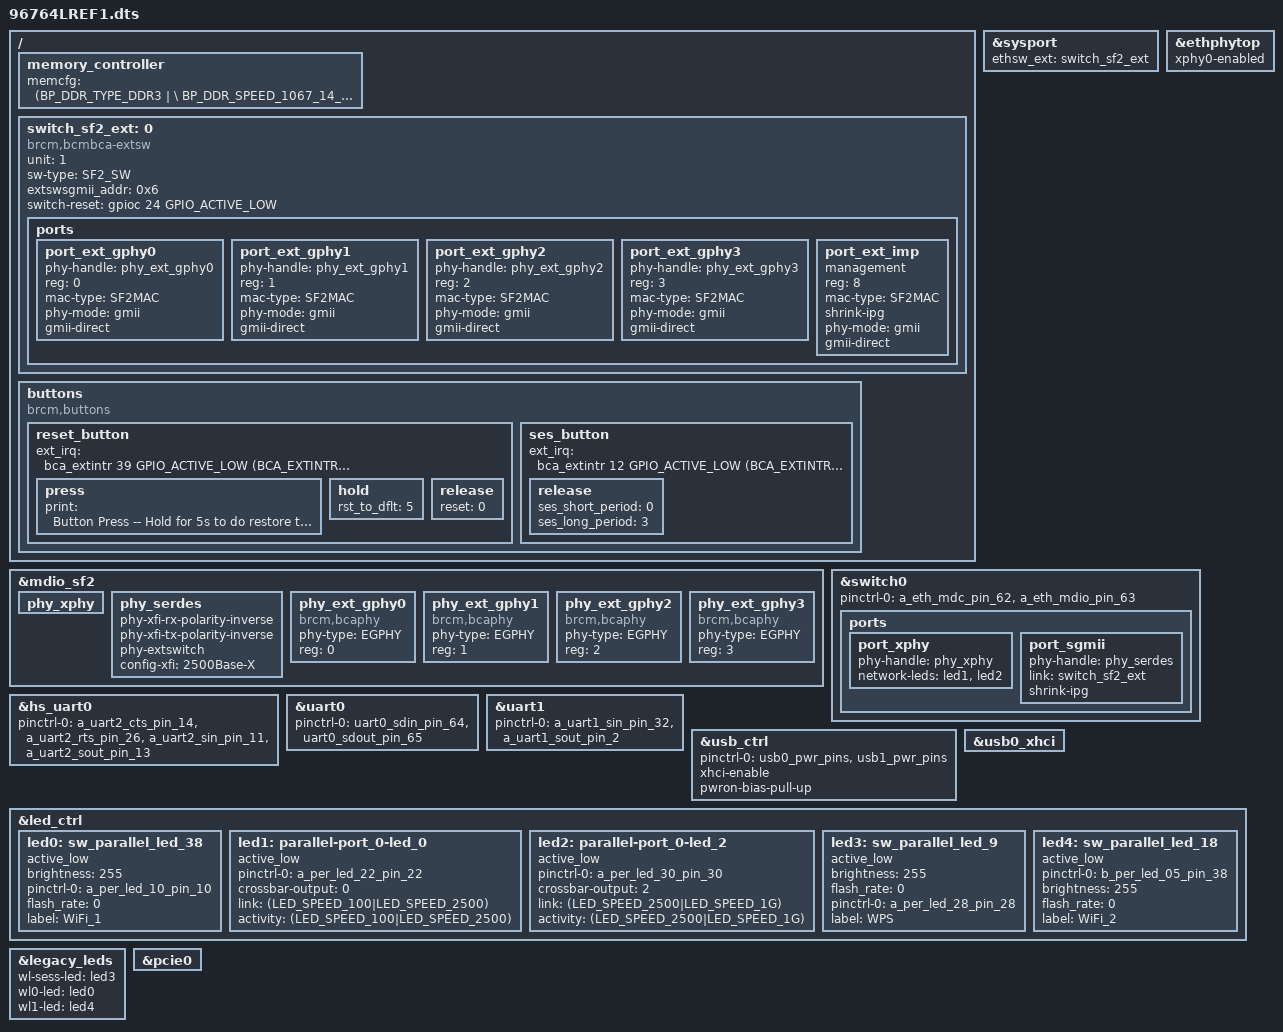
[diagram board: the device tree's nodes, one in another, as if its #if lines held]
#include "6765.dtsi"
#include "../bcm_voice.dtsi"

/ {

	memory_controller {
		memcfg = <(BP_DDR_TYPE_DDR3       | \
			BP_DDR_SPEED_1067_14_14_14    | \
			BP_DDR_TOTAL_SIZE_512MB      | \
			BP_DDR_DEVICE_WIDTH_16        | \
			BP_DDR_TOTAL_WIDTH_16BIT      | \
			BP_DDR_6765_DEFAULT           | \
			BP_DDR_CONFIG_DEBUG)>;
	};
	
	switch_sf2_ext:0 {
	};
};

/ {
	buttons {
		compatible = "brcm,buttons";
		reset_button {
			ext_irq = <&bca_extintr 39 GPIO_ACTIVE_LOW (BCA_EXTINTR_TYPE_LOW_LEVEL | BCA_EXTINTR_TYPE_SENSE_EDGE)>;
			press {
				print = "Button Press -- Hold for 5s to do restore to default";
			};
			hold {
				rst_to_dflt = <5>;
			};
			release {
				reset = <0>;
			};  
		};
		ses_button {
			ext_irq = <&bca_extintr 12 GPIO_ACTIVE_LOW (BCA_EXTINTR_TYPE_LOW_LEVEL | BCA_EXTINTR_TYPE_SENSE_EDGE)>;
			release {
				ses_short_period = <0>;
				ses_long_period = <3>;
			};
		};
	};    
};

&sysport {
    ethsw_ext = <&switch_sf2_ext>;
};

&mdio_sf2 {
       /* Port PHY mapping:
            port_imp -8#0- port_xhy <----> phy_xphy
                      # #
                      ##5- port_sgmii <-> phy_serdes <--> port_ext_imp -8#0- port_ext_gphy0 <--> phy_ext_gphy0
                                                                        # 1- port_ext_gphy1 <--> phy_ext_gphy1
                                                                        # 2- port_ext_gphy2 <--> phy_ext_gphy2
                                                                        ##3- port_ext_gphy3 <--> phy_ext_gphy3
         */
	phy_xphy {
		status = "okay";
		/delete-property/ pinctrl-names;    // handle in switch probing
		/delete-property/ pinctrl-0;
	};
	phy_serdes {
		phy-xfi-rx-polarity-inverse;
		phy-xfi-tx-polarity-inverse;
		phy-extswitch;
		config-xfi="2500Base-X";
		status = "okay";
	};

	/* PHYs on external SF2 switch */
	phy_ext_gphy0:phy_ext_gphy0 {
		compatible = "brcm,bcaphy";
		phy-type = "EGPHY";
		reg = <0>;
		status = "okay";
	};
	phy_ext_gphy1:phy_ext_gphy1 {
		compatible = "brcm,bcaphy";
		phy-type = "EGPHY";
		reg = <1>;
		status = "okay";
	};
	phy_ext_gphy2:phy_ext_gphy2 {
		compatible = "brcm,bcaphy";
		phy-type = "EGPHY";
		reg = <2>;
		status = "okay";
	};
	phy_ext_gphy3:phy_ext_gphy3 {
		compatible = "brcm,bcaphy";
		phy-type = "EGPHY";
		reg = <3>;
		status = "okay";
	};
};

&switch_sf2_ext {                       /* linux/uboot: external sf2 */
	unit = <1>;
	sw-type = "SF2_SW";

	compatible = "brcm,bcmbca-extsw";
	extswsgmii_addr = <0x6>;
	switch-reset = <&gpioc 24 GPIO_ACTIVE_LOW>;

	ports {
		#address-cells = <1>;
		#size-cells = <0>;

		port_ext_gphy0 {
			phy-handle = <&phy_ext_gphy0>;
			reg = <0>;
			mac-type = "SF2MAC";
			phy-mode = "gmii";
			gmii-direct;
			status = "okay";
		};
		port_ext_gphy1 {
			phy-handle = <&phy_ext_gphy1>;
			reg = <1>;
			mac-type = "SF2MAC";
			phy-mode = "gmii";
			gmii-direct;
			status = "okay";
		};
		port_ext_gphy2 {
			phy-handle = <&phy_ext_gphy2>;
			reg = <2>;
			mac-type = "SF2MAC";
			phy-mode = "gmii";
			gmii-direct;
			status = "okay";
		};
		port_ext_gphy3 {
			phy-handle = <&phy_ext_gphy3>;
			reg = <3>;
			mac-type = "SF2MAC";
			phy-mode = "gmii";
			gmii-direct;
			status = "okay";
		};
		port_ext_imp {
			management;                     /* sf2_ext.p8 <--> root.p5  when P8_SGMII_SEL=1 */
			reg = <8>;
			mac-type = "SF2MAC";
			shrink-ipg;
			phy-mode = "gmii";
			gmii-direct;
			status = "okay";
		};
	};
};

&ethphytop {
    xphy0-enabled;
    status = "okay";
};

&switch0 {
	pinctrl-0 = <&a_eth_mdc_pin_62 &a_eth_mdio_pin_63>;
	pinctrl-names = "default";

	ports {
		port_xphy {
			phy-handle = <&phy_xphy>;
			network-leds=<&led1 &led2>;
			status = "okay";
		};
		port_sgmii {
			phy-handle = <&phy_serdes>;
			link = <&switch_sf2_ext>;
			shrink-ipg;
			status = "okay";
		};
	};
};

&hs_uart0 {
	pinctrl-0 = <&a_uart2_cts_pin_14 &a_uart2_rts_pin_26 &a_uart2_sin_pin_11 &a_uart2_sout_pin_13>;
	pinctrl-names = "default";
	status = "okay";
};

&uart0 {
    pinctrl-names = "default";
    pinctrl-0 = <&uart0_sdin_pin_64 &uart0_sdout_pin_65>;
    status = "okay";
};

&uart1 {
    pinctrl-names = "default";
    pinctrl-0 = <&a_uart1_sin_pin_32 &a_uart1_sout_pin_2>;
    status = "okay";
};

&usb_ctrl {
	pinctrl-names="default";
	pinctrl-0 = <&usb0_pwr_pins &usb1_pwr_pins>;
	status = "okay";
	xhci-enable;
	pwron-bias-pull-up;
};

&usb0_xhci {
	status = "okay";
};

&led_ctrl {

	led0: sw_parallel_led_38 {
		active_low; 
		brightness = <255>;
		pinctrl-0 = <&a_per_led_10_pin_10>;
		flash_rate = <0>;
		status = "okay";
		label = "WiFi_1";
	};
	led1: parallel-port_0-led_0 {
		active_low;
		pinctrl-0 = <&a_per_led_22_pin_22>;
		crossbar-output = <0>;
		link = <(LED_SPEED_100|LED_SPEED_2500)>;
		activity = <(LED_SPEED_100|LED_SPEED_2500)>;
		status="okay";
	};
	led2: parallel-port_0-led_2 {
		active_low;
		pinctrl-0 = <&a_per_led_30_pin_30>;
		crossbar-output = <2>;
		link = <(LED_SPEED_2500|LED_SPEED_1G)>;
		activity = <(LED_SPEED_2500|LED_SPEED_1G)>;
		status="okay";
	};
	led3: sw_parallel_led_9 {
		active_low; 
		brightness = <255>;
		flash_rate = <0>;
		pinctrl-0 = <&a_per_led_28_pin_28>;
		status = "okay";
		label = "WPS";
	};

	led4: sw_parallel_led_18 {
		active_low; 
		pinctrl-0 = <&b_per_led_05_pin_38>;
		brightness = <255>;
		flash_rate = <0>;
		status = "okay";
		label = "WiFi_2";
	};

};

&legacy_leds {
	wl-sess-led = <&led3>;
	wl0-led = <&led0>;
	wl1-led = <&led4>;
};

#if defined(CONFIG_BCM_PCIE_HCD) || defined(CONFIG_BCM_PCIE_HCD_MODULE)
/**********************************************************************/
/* GPIO: Add one define per GPIO (individual or shared) regulator     */
/*       - Skip if no GPIO regulators in use                          */
/**********************************************************************/
#define PCIE0_REG_GPIO    27    /* PCIE0_PWR_CTRL for vreg_pcie0 node */

#include "../bcm_wlan_regulator.dtsi"

/**********************************************************************/
/* Shared: Add brcm,supply-names = "vreg-pcieX" for shared PCIe nodes */
/*         - Skip if not using shared GPIO regulators                 */
/**********************************************************************/

/**********************************************************************/
/* PCIe: Add status = "okay" for each PCIe slots of this boiard       */
/*       - Skip if this is a derivative board (already done in base)  */
/**********************************************************************/
&pcie0 {
	status = "okay";
};
#endif //#if defined(CONFIG_BCM_PCIE_HCD) || defined(CONFIG_BCM_PCIE_HCD_MODULE)
